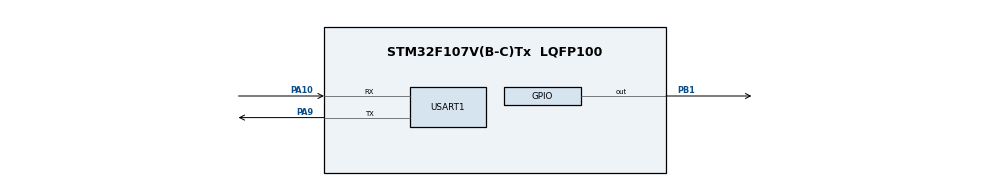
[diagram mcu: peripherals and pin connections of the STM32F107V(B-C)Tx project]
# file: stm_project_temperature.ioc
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Mcu.Family=STM32F1
Mcu.Name=STM32F107V(B-C)Tx
Mcu.Package=LQFP100
NVIC.PriorityGroup=NVIC_PRIORITYGROUP_4
NVIC.USART1_IRQn=true\:0\:0\:false\:false\:true\:true\:true\:true
OSC_IN.Mode=HSE-External-Oscillator
OSC_IN.Signal=RCC_OSC_IN
OSC_OUT.Mode=HSE-External-Oscillator
OSC_OUT.Signal=RCC_OSC_OUT
PA10.Mode=Asynchronous
PA10.Signal=USART1_RX
PA13.Mode=Serial_Wire
PA13.Signal=SYS_JTMS-SWDIO
PA14.Mode=Serial_Wire
PA14.Signal=SYS_JTCK-SWCLK
PA9.Mode=Asynchronous
PA9.Signal=USART1_TX
PB1.Signal=GPIO_Output
ProjectManager.HeapSize=0x200
ProjectManager.StackSize=0x400
ProjectManager.TargetToolchain=EWARM V8.32
RCC.USBFreq_Value=10666666.666666666
USART1.VirtualMode=VM_ASYNC
board=custom

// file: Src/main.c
/* USER CODE BEGIN Header */
/**
 ******************************************************************************
 * @file           : main.c
 * @brief          : Main program body
 ******************************************************************************
 * @attention
 *
 * Copyright (c) 2024 STMicroelectronics.
 * All rights reserved.
 *
 * This software is licensed under terms that can be found in the LICENSE file
 * in the root directory of this software component.
 * If no LICENSE file comes with this software, it is provided AS-IS.
 *
 ******************************************************************************
 */
/* USER CODE END Header */
#include "main.h"
#include "gpio.h"
#include "usart.h"

/* USER CODE BEGIN Includes */
#include "DHT.h"
#include "str_queue.h"
#include <stdint.h>
#include <stdlib.h>
/* USER CODE END Includes */

void SystemClock_Config(void);

/* USER CODE BEGIN 0 */
Queue messages;
bool transmiting = false;

void HAL_UART_TxCpltCallback(UART_HandleTypeDef *huart) {
    if (!isEmpty(&messages)) {
        const uint8_t *message = dequeue(&messages);
        HAL_UART_Transmit_IT(&huart1, (uint8_t *)message, sizeof(message));
    } else {
        transmiting = false;
    }
}

void _serial_log(const uint8_t *message) {
    enqueue(&messages, message);
    if (!transmiting) {
        transmiting = true;
        HAL_UART_TxCpltCallback(&huart1);
    }
}

void serial_log(const uint8_t *message) {
    uint8_t eol[] = "\r\n";
    _serial_log(eol);
    _serial_log(message);
}

DHT_DataTypedef DHT11_Data;
/* USER CODE END 0 */

int main(void) {

    /* USER CODE BEGIN 1 */
    initStrQueue(&messages);
    /* USER CODE END 1 */

    /* MCU
     * Configuration--------------------------------------------------------*/

    /* Reset of all peripherals, Initializes the Flash interface and the
     * Systick. */
    HAL_Init();

    /* Configure the system clock */
    SystemClock_Config();

    /* Initialize all configured peripherals */
    MX_GPIO_Init();
    MX_USART1_UART_Init();

    /* Infinite loop */
    /* USER CODE BEGIN WHILE */
    while (1) {
        uint8_t data[] = "Hello, World!";
        serial_log(data);

        HAL_GPIO_TogglePin(GPIOB, GPIO_PIN_1);

        DHT_GetData(&DHT11_Data);

        char buffer[50];

        itoa((int)DHT11_Data.Temperature, buffer, 10);
        serial_log(buffer);

        HAL_Delay(3000);

        itoa((int)DHT11_Data.Humidity, buffer, 10);
        serial_log(buffer);

        HAL_Delay(3000);
        /* USER CODE END WHILE */

    }
}

void SystemClock_Config(void) {
    RCC_OscInitTypeDef RCC_OscInitStruct = {0};
    RCC_ClkInitTypeDef RCC_ClkInitStruct = {0};

    /** Initializes the RCC Oscillators according to the specified parameters
     * in the RCC_OscInitTypeDef structure.
     */
    RCC_OscInitStruct.OscillatorType = RCC_OSCILLATORTYPE_HSI;
    RCC_OscInitStruct.HSIState = RCC_HSI_ON;
    RCC_OscInitStruct.HSICalibrationValue = RCC_HSICALIBRATION_DEFAULT;
    RCC_OscInitStruct.PLL.PLLState = RCC_PLL_NONE;
    RCC_OscInitStruct.PLL2.PLL2State = RCC_PLL_NONE;
    if (HAL_RCC_OscConfig(&RCC_OscInitStruct) != HAL_OK) {
        Error_Handler();
    }

    /** Initializes the CPU, AHB and APB buses clocks
     */
    RCC_ClkInitStruct.ClockType = RCC_CLOCKTYPE_HCLK | RCC_CLOCKTYPE_SYSCLK |
                                  RCC_CLOCKTYPE_PCLK1 | RCC_CLOCKTYPE_PCLK2;
    RCC_ClkInitStruct.SYSCLKSource = RCC_SYSCLKSOURCE_HSI;
    RCC_ClkInitStruct.AHBCLKDivider = RCC_SYSCLK_DIV1;
    RCC_ClkInitStruct.APB1CLKDivider = RCC_HCLK_DIV1;
    RCC_ClkInitStruct.APB2CLKDivider = RCC_HCLK_DIV1;

    if (HAL_RCC_ClockConfig(&RCC_ClkInitStruct, FLASH_LATENCY_0) != HAL_OK) {
        Error_Handler();
    }

    /** Configure the Systick interrupt time
     */
    __HAL_RCC_PLLI2S_ENABLE();
}

void Error_Handler(void) {
    /* USER CODE BEGIN Error_Handler_Debug */
    /* User can add his own implementation to report the HAL error return state
     */
    __disable_irq();
    while (1) {
    }
    /* USER CODE END Error_Handler_Debug */
}

#ifdef USE_FULL_ASSERT
/**
 * @brief  Reports the name of the source file and the source line number
 *         where the assert_param error has occurred.
 * @param  file: pointer to the source file name
 * @param  line: assert_param error line source number
 * @retval None
 */
void assert_failed(uint8_t *file, uint32_t line) {
    /* USER CODE BEGIN 6 */
    /* User can add his own implementation to report the file name and line
       number, ex: printf("Wrong parameters value: file %s on line %d\r\n",
       file, line) */
    /* USER CODE END 6 */
}
#endif /* USE_FULL_ASSERT */
